# USB0_VBP2AHB_WRAP_CONTROLLER_VBP_USB3_CORE_GBL register map
Vendor: Texas Instruments
Peripheral module from a debugger description file (folder J722S).
Registers are 32-bit, read-write, reset 0x0 unless marked. A register's access mark holds for its fields unless they carry their own. Offsets are as the file gives them; lines under a group give offsets from that group; [hi:lo] are bit positions; {n}, {i} and the like mark numbered series; 'fields as' and 'values as' point back to an identical list; <NAME> marks a mode.

## USB0_VBP2AHB_WRAP_CONTROLLER_VBP_USB3_CORE_GBL (part 1 of 4)
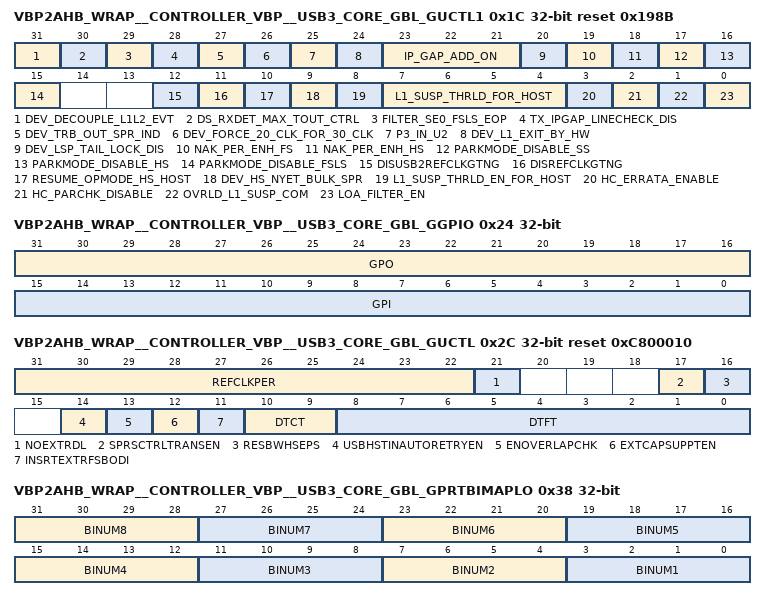
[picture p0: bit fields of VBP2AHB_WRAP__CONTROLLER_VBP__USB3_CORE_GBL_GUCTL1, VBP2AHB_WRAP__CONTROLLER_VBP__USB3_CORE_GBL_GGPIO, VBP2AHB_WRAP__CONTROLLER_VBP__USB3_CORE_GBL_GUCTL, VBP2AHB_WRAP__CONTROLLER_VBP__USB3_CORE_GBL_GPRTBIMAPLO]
0x1C VBP2AHB_WRAP__CONTROLLER_VBP__USB3_CORE_GBL_GUCTL1 access per field reset 0x198B — Global User Control Register 1
  [31] DEV_DECOUPLE_L1L2_EVT rw — DEV_DECOUPLE_L1L2_EVT - 0: Default behavior, no change in device events L1/L2U3 events are not decoupled [old behavior of v2.90a and before] - 1: Feature enabled, L1 and L2 events are separated when operating in 2.0 mode. Separate event enable bits for L1 suspend and wake events. This bit is applicable for device mode only. If this feature is enabled, L1 suspend and wake events have individual controls to enable/mask them. Enable this feature if you want to get L1 [LPM] events separtely and not combined with L2 events when operating in 2.0 speeds.
  [30] DS_RXDET_MAX_TOUT_CTRL rw — DS_RXDET_MAX_TOUT_CTRL This bit is used to control the tRxDetectTimeoutDFP timer for the SuperSpeed link. - 0: Default behavior. 12ms is used as tRxDetectTimeoutDFP. - 1: 120ms is used as the tRxDetectTimeoutDFP. This bit is used only in host mode. For more details, refer to ECN020 for USB 3.0 Specification.
  [29] FILTER_SE0_FSLS_EOP rw — FILTER_SE0_FSLS_EOP - 0: Default behavior, no change in Linestate check for SE0 detection in FS/LS - 1: Feature enabled, FS/LS SE0 is filtered for 2 clocks for detecting EOP This bit is applicable for FS/LS operation. If this feature is enabled, then SE0 on the linestate is validated for 2 consecutive utmi/ulpi clock edges for EOP detection. This feature is applicable only in FS in device mode and FS/LS mode of operation in host mode. Device mode: FS - If GUCTL1.FILTER_SE0_FSLS_EOP is set, then for device LPM handshake, the controller will ignore single SE0 glitch on the linestate during transmit. Only 2 or more SE0 is considered as a valid EOP on FS. Host mode: FS/LS - If GUCTL1.FILTER_SE0_FSLS_EOP is set, then the controller will ignore single SE0 glitch on the linestate during transmit. Only 2 or more SE0 is considered as a valid EOP on FS/LS port. Enable this feature if the LineState has SE0 glitches during transmission. This bit is quasi-static, that is, it must not be changed during device operation.
  [28] TX_IPGAP_LINECHECK_DIS rw — TX_IPGAP_LINECHECK_DIS - 0: Default behavior, no change in Linestate check - 1: Feature enabled, 2.0 MAC disables Linestate check during HS transmit This bit is applicable for HS operation of u2mac. If this feature is enabled, then the 2.0 mac operating in HS ignores the UTMI/ULPI Linestate during the transmit of a token [during token-to-token and token-to-data IPGAP]. When enabled, the controller implements a fixed 40-bit TxEndDelay after the packet is given on UTMI and ignores the Linestate during this time. This feature is applicable only in HS mode of operation. Device mode: If GUCTL1.TX_IPGAP_LINECHECK_DIS is set, then for device LPM handshake, the controller will ignore the linestate after TX and wait for fixed clocks [40 bit times equivalent] after transmitting ACK on utmi. Host mode: If GUCTL1.TX_IPGAP_LINECHECK_DIS is set, then the ipgap between [tkn to tkn/data] is added by 40 bit times of TXENDDELAY, and linestate is ignored during this 40 bit times delay. Enable this bit if the LineState will not reflect the expected line state [J] during transmission. This bit is quasi-static, that is, it must not be changed during device operation.
  [27] DEV_TRB_OUT_SPR_IND rw — DEV_TRB_OUT_SPR_IND - 0: Default behavior, no change in TRB status dword - 1: Feature enabled, OUT TRB status indicates Short Packet This bit is applicable for device mode only [and ignored in host mode]. If the device application [software/hardware] wants to know if a short packet was received for an OUT in the TRB status itself, then this feature can be enabled, so that a bit is set in the TRB writeback in the buf_size dword. Bit[26] - SPR of the {trbstatus, RSVD, SPR, PCM1, bufsize} dword will be set during an OUT transfer TRB write back if this is the last TRB used for that transfer descriptor. This bit is quasi-static, that is, it must not be changed during device operation.
  [26] DEV_FORCE_20_CLK_FOR_30_CLK rw — DEV_FORCE_20_CLK_FOR_30_CLK - 0: Default behavior, Uses 3.0 clock when operating in 2.0 mode - 1: Feature enabled This bit is applicable [and to be set] for device mode [DCFG.Speed != SS] only. In the 3.0 device controller, if the controller is programmed to operate in 2.0 only [that is, Device Speed is programmed to 2.0 speeds in DCFG[Speed]], then setting this bit makes the internal 2.0 [utmi/ulpi] clock to be routed as the 3.0 [pipe] clock. Enabling this feature allows the pipe3 clock to be not-running when forcibly operating in 2.0 device mode. Note: - When using this feature, all pipe3 inputs must be in inactive mode. In particular, the pipe3 clocks must not be running and the pipe3_phystatus_async must be tied to 0. This bit should not be set if the controller is programmed to operate in SuperSpeed mode [even when it falls back to 2.0]. - This bit is quasi-static, that is, it must not be changed during operation. - If the parameter DWC_USB3_REMOVE_PIPE_CLK_MUX_FOR_20_MODE is enabled, then muxing 2.0 clock/signals to pipe_clk/signals have to be done outside the controller for this feature to work.
  [25] P3_IN_U2 rw — P3_IN_U2 - 0: Default behavior, When SuperSpeed link is in U2, PowerState P2 is attempted on the PIPE Interface. - 1: When SuperSpeed link is in U2, PowerState P3 is attempted if GUSB3PIPECTL[17] is set. Setting this bit enables P3 Power State when the SuperSpeed link is in U2. Another Power Saving option. Check with your PHY vendor before enabling this option.When setting this bit to 1 to enable P3 in P2, GUSB3PIPECTL[27] should be set to 0 to make sure that the U2 exit is attempted in P0. This bit should be set only when GCTL.SOFITPSYNC=1 or GFLADJ.GFLADJ_REFCLK_LPM_SEL=1.
  [24] DEV_L1_EXIT_BY_HW rw — DEV_L1_EXIT_BY_HW - 0: Default behavior, disables device L1 hardware exit logic - 1: feature enabled This bit is applicable for device mode [2.0] only. This field enables device controller sending remote wakeup for L1 if the device becomes ready for sending/accepting data when in L1 state. If the host expects the device to send remote wakeup signaling to resume after going into L1 in flow controlled state, then this bit can be set to send the remote wake signal automatically when the device controller becomes ready. This hardware remote wake feature is applicable only to bulk and interrupt transfers, and not for Isoch/Control - When control transfers are in progress, the LPM will be rejected [NYET response]. Only after control transfers are completed [either with ACK/STALL], LPM will be accepted - For Isoch transfers, the host needs to do the wake-up and start the transfer. Device controller will not do remote-wakeup when Isoch endpoints get ready. The device SW needs to keep the GUSB2PHYCFG[EnblSlpM] reset in order to keep the PHY clock to be running for keeping track of SOF intervals. - When L1 hibernation is enabled, the controller will not do automatic exit for hibernation requests thru L1. This bit is quasi-static, that is, it must not be changed during device operation.
  [23:21] IP_GAP_ADD_ON rw — This register field is used to add on to the default inter packet gap setting in the USB 2.0 MAC. This should be programmed to a non zero value only in case where you need to increase the default inter packet delay calculations in the USB 2.0 MAC module DWC_usb3_u2mac.v
  [20] DEV_LSP_TAIL_LOCK_DIS rw — DEV_LSP_TAIL_LOCK_DIS - 0: Default behavior, enables device lsp lock logic for tail TRB update - 1: Fix disabled This is a bug fix for STAR 9000716195 that affects the CSP mode for OUT endpoints in device mode. The issue is that tail TRB index is not synchronized with the cache Scratchpad bytecount update. If the fast-forward request comes in-between the bytecount update on a newly fetched TRB and the tail-index write update in TPF, the RDP works on an incorrect tail index and misses the byte count decrement for the newly fetched TRB in the fast-forwarding process. This fix needs to be present all the times.
  [19] NAK_PER_ENH_FS rw — NAK_PER_ENH_FS - 1: Enables performance enhancement for FS async endpoints in the presence of NAKs - 0: Enhancement not applied If a periodic endpoint is present , and if a bulk endpoint which is also active is being NAKed by the device, then this could result in a decrease in performance of other Full Speed bulk endpoint which is ACked by the device. Setting this bit to 1, will enable the host controller to schedule more transactions to the async endpoints [bulk/ control] and hence will improve the performance of the bulk endpoint. This control bit should be enabled only if the existing performance with the default setting is not sufficient for your FullSpeed application. Setting this bit will only control, and is only required for Full Speed transfers.
  [18] NAK_PER_ENH_HS rw — NAK_PER_ENH_HS - 1: Enables performance enhancement for HS async endpoints in the presence of NAKs - 0: Enhancement not applied If a periodic endpoint is present, and if a bulk endpoint which is also active is being NAKed by the device, then this could result in decrease in performance of other High Speed bulk endpoint which is ACked by the device. Setting this bit to 1, will enable the host controller to schedule more transactions to the async endpoints [ bulk/ control] and hence will improve the performance of the bulk endpoint. This control bit should be enabled only if the existing performance with the default setting is not sufficient for your HighSpeed application. Setting this bit will only control, and is only required for High Speed transfers.
  [17] PARKMODE_DISABLE_SS rw — PARKMODE_DISABLE_SS This bit is used only in host mode, and is for debug purpose only. When this bit is set to '1' all SS bus instances in park mode are disabled.
  [16] PARKMODE_DISABLE_HS rw — PARKMODE_DISABLE_HS This bit is used only in host mode. When this bit is set to '1' all HS bus instances park mode are disabled. To improve performance in park mode, the xHCI scheduler queues in three requests of 4 packets each for High Speed asynchronous endpoints in a micro-frame. But if a device is slow and if it NAKs more than 3 times, then it is rescheduled only in the next micro-frame. This could decrease the performance of a slow device even further. In a few high speed devices [such as Sandisk Cruzer Blade 4GB VID:1921, PID:21863 and Flex Drive VID:3744, PID:8552] when an IN request is sent within 900ns of the ACK of the previous packet, these devices send a NAK. When connected to these devices, if required, the software can disable the park mode if you see performance drop in your system. When park mode is disabled, pipelining of multiple packet is disabled and instead one packet at a time is requested by the scheduler. This allows up to 12 NAKs in a micro-frame and improves performance of these slow devices.
  [15] PARKMODE_DISABLE_FSLS rw — PARKMODE_DISABLE_FSLS This bit is used only in host mode, and is for debug purpose only. When this bit is set to '1' all FS/LS bus instances in park mode disabled.
  [12] DISUSB2REFCLKGTNG ro — Disable ref_clk gating for 2.0 PHY [DisUSB2RefClkGtng] If ref_clk gating is disabled, then the ref_clk input cannot be turned off to the USB 2.0 PHY and controller. This is independent of the GCTL[DisClkGtng] setting. - 1'b0: ref_clk gating enabled for USB 2.0 PHY - 1'b1: ref_clk gating disabled for USB 2.0 PHY
  [11] DISREFCLKGTNG ro — Disable ref_clk gating [DisRefClkGtng] If the ref_clk gating is disabled then input ref_clk cannot be turned off to SSPHY and controller. This is independent of GCTL[DisClkGtng] setting. - 1'b0: ref_clk gating Enabled for SSPHY - 1'b1: ref_clk gating Disabled for SSPHY
  [10] RESUME_OPMODE_HS_HOST rw — RESUME_OPMODE_HS_HOST This bit is used only in host mode, and is for USB 2.0 opmode behavior in HS Resume. - When this bit is set to '1', the UTMI/ULPI opmode will be changed to normal along with HS terminations after EOR. This option is to support certain legacy UTMI/ULPI PHYs. - When this bit is set to '0', the UTMI/ULPI opmode will be changed to normal 2us after HS terminations change after EOR. This is the default behavior.
  [9] DEV_HS_NYET_BULK_SPR rw — DEV_HS_NYET_BULK_SPR - 0: Default behavior, no change in device response - 1: Feature enabled, HS bulk OUT short packet gets NYET response This bit is applicable for device mode only [and ignored in host mode] to be used in 2.0 operation. If this bit is set, the device controller sends NYET response instead of ACK response for a successfully received bulk OUT short packet. If NYET is sent after receiving short packet, then the host would PING before sending the next OUT. this improves the performance as well as clears up the buffer/cache on the host side. Internal to the device controller, short packet [SPR=1] processing takes some time, and during this time, the USB is flow controlled. With NYET response instead of ACK on short packet, the host does not send another OUT-DATA without pinging in HS mode. This bit is quasi-static, that is, it must not be changed during device operation.
  [8] L1_SUSP_THRLD_EN_FOR_HOST rw — L1_SUSP_THRLD_EN_FOR_HOST This bit is used only in host mode. The host controller asserts the utmi_l1_suspend_n and utmi_sleep_n output signals [see LPM Interface Signals table in the Databook] as follows: The controller asserts the utmi_l1_suspend_n signal to put the PHY into deep low-power mode in L1 when both of the following are true: - The HIRD/BESL value used is greater than or equal to the value in L1_SUSP_THRLD_FOR_HOST field. - The L1_SUSP_THRLD_EN_FOR_HOST bit is set to 1'b1. The controller asserts utmi_sleep_n on L1 when one of the following is true: - The HIRD/BESL value used is less than the value in L1_SUSP_THRLD_FOR_HOST field. - The L1_SUSP_THRLD_EN_FOR_HOST bit is set to 1'b0.
  [7:4] L1_SUSP_THRLD_FOR_HOST rw — L1_SUSP_THRLD_FOR_HOST This field is effective only when the L1_SUSP_THRLD_EN_FOR_HOST bit is set to 1. For more details, refer to the description of the L1_SUSP_THRLD_EN_FOR_HOST bit.
  [3] HC_ERRATA_ENABLE rw — Host ELD Enable [HELDEn] When this bit is set to 1, it enables the Exit Latency Delta [ELD] support defined in the xHCI 1.0 Errata. This bit is used only in the host mode. This bit has to be set to 1 in Host mode.
  [2] HC_PARCHK_DISABLE rw — Host Parameter Check Disable [HParChkDisable] When this bit is set to '0' [by default], the xHC checks that the input slot/EP context fields comply to the xHCI Specification. Upon detection of a parameter error during command execution, the xHC generates an event TRB with completion code indicating 'PARAMETER ERROR'. When the bit is set to '1', the xHC does not perform parameter checks and does not generate 'PARAMETER ERROR' completion code.
  [1] OVRLD_L1_SUSP_COM rw — OVRLD_L1_SUSP_COM If this bit is set, the utmi_l1_suspend_com_n is overloaded with the utmi_sleep_n signal. This bit is usually set if the PHY stops the port clock during L1 sleep condition. Note: The recommended connection for the SUSPENDM/SLEEPM signals to the PHY with respect to this bit is as follows. For non-zero ports: Connect: - utmi_sleep_n[n] to SLEEPM[n] - [utmi_suspend_n[n] & utmi_l1_suspend_n[n]] to SUSPENDM[n] - USB2 PHYCLK[n] to utmi_clk[n] GUCTL1.OVRLD_L1_SUSP_COM impacts only Port0. For Port0: For Synopsys PHY, GUSB2PHYCFGn.U2_FREECLK_EXISTS=1. With this connection, the PHY keeps PLL active so that FREECLK is always available irrespective of suspend/sleep. - Connect USB2 PHY COMMONONN to 0. - Connect utmi_sleep_n[0] to SLEEPM[0]. - Connect [utmi_suspend_n[0] & utmi_l1_suspend_n[0]] to SUSPENDM[0]. - Connect USB2 PHY FREECLK to utmi_clk[0]. - Leave utmi_suspend_com_n, utmi_l1_suspend_com_n unconnected. - GUCTL1.OVRLD_L1_SUSP_COM can be set to any value. For Third Party PHY, GUSB2PHYCFGn.U2_FREECLK_EXISTS=0. With this connection the PHY can shut off all the clocks when the required conditions are met [like, GUSB2PHYCFGn[8,6], GUCTL1[1], GFLADJ[23], GCTL[10], Suspend condition, HW LPM enable etc]. - Connect -utmi_suspend_com_n to SUSPENDM[0] [or equivalent]. - Connect -utmi_l1_suspend_com_n to SLEEPM[0] [or equivalent]. - Connect PHYCLK0 [first port clock] to utmi_clk[0]. - Leave utmi_suspend_n[0], utmi_l1_suspend_ n[0], utmi_sleep_n[0] unconnected. - Set GUCTL1.OVRLD_L1_SUSP_COM to 1'b1.
  [0] LOA_FILTER_EN rw — LOA_FILTER_EN If this bit is set, the USB 2.0 port babble is checked at least three consecutive times before the port is disabled. This prevents false triggering of the babble condition when using low quality cables. Note: This bit is valid only in host mode.
0x20 VBP2AHB_WRAP__CONTROLLER_VBP__USB3_CORE_GBL_GSNPSID ro reset 0x5533330B — Global Synopsys ID Register This is a read-only register that contains the release number of the controller.
  [31:0] SYNOPSYSID — Synopsys ID - SynopsysID[31:16] indicates Core Identification Number. 0x5533 is ASCII for U3 [DWC_usb3]. - SynopsysID[15:0] indicates the release number. Current Release is 3.30a. Software uses this register to configure release-specific features in the driver.
0x24 VBP2AHB_WRAP__CONTROLLER_VBP__USB3_CORE_GBL_GGPIO access per field — Global General Purpose Input/Output Register The application can use this register for general purpose input and output ports or for debugging.
  [31:16] GPO rw — General Purpose Output The value of this field is driven out on the gp_out[15:0] output port.
  [15:0] GPI ro — General Purpose Input The read value of this field reflects the gp_in[15:0] input signal value. Note: Register bit-bash test should not check for reset value of this field since its not predictable. depends on the gp_in port.
0x28 VBP2AHB_WRAP__CONTROLLER_VBP__USB3_CORE_GBL_GUID — Global User ID Register This is a read/write register containing the User ID. The power-on value for this register is specified as the User Identification Register. Power-on value during coreConsultant configuration (parameter DWC_USB3_USERID). This register can be used in the following ways: - To store the version or revision of your system. - To store hardware configurations that are outside the controller. - As a scratch register.
  [31:0] USERID — USERID Application-programmable ID field.
0x2C VBP2AHB_WRAP__CONTROLLER_VBP__USB3_CORE_GBL_GUCTL reset 0xC800010 — Global User Control Register: This register provides a few options for the software to control the controller behavior in the Host mode. Most of the options are used to improve host inter-operability with different devices.
  [31:22] REFCLKPER — REFCLKPER This field indicates in terms of nano seconds the period of ref_clk. The default value of this register is set to 'h8 [8ns/125 MHz]. This field needs to be updated during power-on initialization, if GCTL.SOFITPSYNC or GFLADJ.GFLADJ_REFCLK_LPM_SEL is set to '1'. The programmable maximum value is 62ns, and the minimum value is 8ns. You must use a reference clock with a period that is an integer multiple, so that ITP can meet the jitter margin of 32ns. The allowable ref_clk frequencies whose period is not integer multiples are 16/17/19.2/24/39.7MHz. This field must not be set to '0' at any time. If you never plan to use this feature, then set this field to 'h8, the default value.
  [21] NOEXTRDL — No Extra Delay Between SOF and the First Packet[NoExtrDl] Some HS devices misbehave when the host sends a packet immediately after a SOF. However, adding an extra delay between a SOF and the first packet can reduce the USB data rate and performance. This bit is used to control whether the host must wait for 2 microseconds before it sends the first packet after a SOF, or not. User can set this bit to one to improve the performance if those problematic devices are not a concern in the user's host environment. - 1'b0: Host waits for 2 microseconds after a SOF before it sends the first USB packet. - 1'b1: Host doesn't wait after a SOF before it sends the first USB packet.
  [17] SPRSCTRLTRANSEN — Sparse Control Transaction Enable Some devices are slow in responding to Control transfers. Scheduling multiple transactions in one microframe/frame can cause these devices to misbehave. If this bit is set to 1'b1, the host controller schedules transactions for a Control transfer in different microframes/frames.
  [16] RESBWHSEPS — Reserving 85% Bandwidth for HS Periodic EPs [ResBwHSEPS] By default, HC reserves 800f the bandwidth for periodic EPs. If this bit is set, the bandwidth is relaxed to 85% to accommodate two high speed, high bandwidth ISOC EPs. USB 2.0 required 800andwidth allocated for ISOC traffic. If two High-bandwidth ISOC devices [HD Webcams] are connected, and if each requires 1024-bytes X 3 packets per Micro-Frame, then the bandwidth required is around 82%. If this bit is set, then it is possible to connect two Webcams of 1024bytes X 3 paylod per Micro-Frame each. Otherwise, you may have to reduce the resolution of the Webcams. This bit is valid in Host and DRD configuration and is used in host mode operation only. Ignore this bit in device mode.
  [14] USBHSTINAUTORETRYEN — Host IN Auto Retry [USBHstInAutoRetryEn] When set, this field enables the Auto Retry feature. For IN transfers [non-isochronous] that encounter data packets with CRC errors or internal overrun scenarios, the auto retry feature causes the Host controller to reply to the device with a non-terminating retry ACK [that is, an ACK transaction packet with Retry = 1 and NumP != 0]. If the Auto Retry feature is disabled [default], the controller will respond with a terminating retry ACK [that is, an ACK transaction packet with Retry = 1 and NumP = 0]. - 1'b0: Auto Retry Disabled - 1'b1: Auto Retry Enabled Note: When enabling Auto Retry feature, if the system latency is large enough to cause the internal PSQ full [PSQ can be full as the result of messages not being processed because of pending fetches before flushing the TxQ due to NRDY/ERDY conditions], then the host controller can generate a transaction error.
  [13] ENOVERLAPCHK — Enable Check for LFPS Overlap During Remote Ux Exit: If this bit is set to, - 1'b1: The SuperSpeed link when exiting U1/U2/U3 waits for either the remote link LFPS or TS1/TS2 training symbols before it confirms that the LFPS handshake is complete. This is done to handle the case where the LFPS glitch causes the link to start exiting from the low power state. Looking for the LFPS overlap makes sure that the link partner also sees the LFPS. - 1'b0: When the link exists U1/U2/U3 because of a remote exit, it does not look for an LFPS overlap.
  [12] EXTCAPSUPPTEN — External Extended Capability Support Enable [ExtCapSuptEN] When set, this field enables extended capabilities to be implemented outside the controller. When the ExtCapSupEN is set and the Debug Capability is enabled, the Next Capability pointer in Debug Capability returns 16. A read to the first DWORD of the last internal extended capability [the xHCI Supported Protocol Capability for USB 3.0 when the Debug Capability is not enabled] returns a value of 4 in the Next Capability Pointer field. This indicates to software that there is another capability four DWORDs after this capability [for example, at address N+16 where N is the address of this DWORD]. If enabled, an external address decoder that snoops the xHC target interface must be implemented. If it sees an access to N+16 or greater, the target access is re-routed to a piece of hardware which returns the external capability pointer register of the new capability and also handles reads/writes to this new capability and the side effects. If disabled, a read to the first DWORD of the last internal extended capability returns 0 in the 'Next Capability Pointer field. This indicates there are no more capabilities.
  [11] INSRTEXTRFSBODI — Insert Extra Delay Between FS Bulk OUT Transactions [InsrtExtrFSBODl]. Some FS devices are slow to receive Bulk OUT data and can get stuck when there are consecutive Bulk OUT transactions with short inter-transaction delays. This bit is used to control whether the host inserts extra delay between consecutive Bulk OUT transactions to a FS Endpoint. - 1'b0: Host doesn't insert extra delay between consecutive Bulk OUT transactions to a FS Endpoint. - 1'b1: Host inserts about 12us extra delay between consecutive Bulk OUT transactions to a FS Endpoint to work around the device issue. Note: Setting this bit to one will reduce the Bulk OUT transfer performance for most of the FS devices.
  [10:9] DTCT — Device Timeout Coarse Tuning [DTCT] This field is a Host mode parameter which determines how long the host waits for a response from device before considering a timeout. The controller first checks the DTCT value. If it is 0, then the timeout value is defined by the DTFT. If it is non-zero, then it uses the following timeout values: - 2'b00: 0 usec -> use DTFT value instead - 2'b01: 500 usec - 2'b10: 1.5 msec - 2'b11: 6.5 msec Note: When the system latency is larger than the programmed DTCT/DTFT value, if the host controller is not able to accept certain transactions on the bus [because of system bus delays], the controller may not release header credits which in turn can cause the host to report a transaction error. Therefore, program this value to be larger than your system delay.
  [8:0] DTFT — Device Timeout Fine Tuning [DTFT] This field is a Host mode parameter which determines how long the host waits for a response from device before considering a timeout. For the DTFT field to take effect, DTCT must be set to 2'b00. The DTFT value is the number of 125 MHz clocks * 256 to count before considering a device timeout. The minimum value of DTFT is 2. For example, if the mac3_clk is 125 MHz clk [8 ns period], this is calculated as follows: [DTFT value] * 256 * [8 ns] Quick Reference: - if DTFT = 0x2, 2*256*8 = 4usec timeout - if DTFT = 0x5, 5*256*8 = 10usec timeout - if DTFT = 0xA, 10*256*8 = 20usec timeout - if DTFT = 0x10, 16*256*8 = 32usec timeout - if DTFT = 0x19, 25*256*8 = 51usec timeout - if DTFT = 0x31, 49*256*8 = 100usec timeout - if DTFT = 0x62, 98*256*8 = 200usec timeout Note: When the system latency is larger than the programmed DTCT/DTFT value, if the host controller is not able to accept certain transactions on the bus [because of system bus delays], the controller may not release header credits which in turn can cause the host to report a transaction error. Therefore, program this value to be larger than your system delay.
0x30 VBP2AHB_WRAP__CONTROLLER_VBP__USB3_CORE_GBL_GBUSERRADDRLO ro — Gobal SoC Bus Error Address Register - Low This is an alternate register for the GBUSERRADDR register.
  [31:0] BUSERRADDR — Bus Address - Low [BusAddrLo] This register contains the lower 32 bits of the first bus address that encountered a SoC bus error. It is valid when the GSTS.BusErrAddrVld field is 1. It can only be cleared by resetting the controller. Note: Only supported in AHB and AXI configurations.
0x34 VBP2AHB_WRAP__CONTROLLER_VBP__USB3_CORE_GBL_GBUSERRADDRHI ro — Gobal SoC Bus Error Address Register - High This is an alternate register for the GBUSERRADDR register.
  [31:0] BUSERRADDR — Bus Address - High [BusAddrHi] This register contains the higher 32 bits of the first bus address that encountered a SoC bus error. It is valid when the GSTS.BusErrAddrVld field is 1. It can only be cleared by resetting the controller. Note: Only supported in AHB and AXI configurations.
0x38 VBP2AHB_WRAP__CONTROLLER_VBP__USB3_CORE_GBL_GPRTBIMAPLO access per field — Global SS Port to Bus Instance Mapping Register - Low This is an alternate register for the GPRTBIMAP register. Register fields are read-write with respect to number of port instantiated. writeAsRead constraint is added to limit side effects for unused fields. For a configuration with number of USB 3.0 ports same as number of SS Bus Instances, do not remap during debug session. If you remap for some reason, then the debug host must be connected to a port which has a dedicated SS Bus Instance. For example, if DWC_USB3_NUM_U3_ROOT_PORTS =3 and DWC_USB3_NUM_SS_USB_INSTANCES=3, and software maps the first SS port to the first SS BI and the second/third port to the second BI, then the debug host can be connected to the first port only. Note: For reset values, refer to the corresponding values in the GPRTBIMAP register.
  [4n-1:4n-4] BINUM{n} ro (n=2..8) — BINUM{n}: SS USB Instance Number for Port {n}. Application-programmable ID field.
  [3:0] BINUM1 rw — BINUM1: SS USB Instance Number for Port 1. Application-programmable ID field.
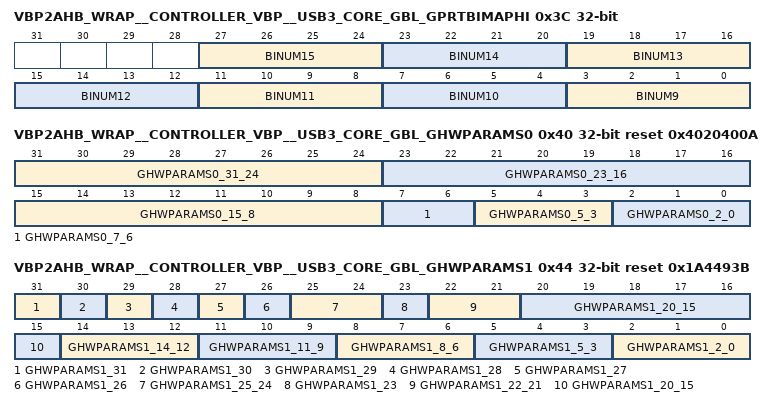
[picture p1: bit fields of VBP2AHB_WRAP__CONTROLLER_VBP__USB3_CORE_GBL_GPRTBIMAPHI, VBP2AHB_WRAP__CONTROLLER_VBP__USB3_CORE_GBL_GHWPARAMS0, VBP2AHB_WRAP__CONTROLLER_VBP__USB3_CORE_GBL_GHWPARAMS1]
0x3C VBP2AHB_WRAP__CONTROLLER_VBP__USB3_CORE_GBL_GPRTBIMAPHI ro — Global SS Port to Bus Instance Mapping Register - High This is an alternate register for the GPRTBIMAP register. For a configuration with number of USB 3.0 ports same as number of SS Bus Instances, do not remap during debug session. If you remap for some reason, then the debug host must be connected to a port which has a dedicated SS Bus Instance. For example, if DWC_USB3_NUM_U3_ROOT_PORTS =3 and DWC_USB3_NUM_SS_USB_INSTANCES=3, and software maps the first SS port to the first SS BI and the second/third port to the second BI, then the debug host can be connected to the first port only. Note: For reset values, refer to the corresponding values in the GPRTBIMAP register.
  [4n-33:4n-36] BINUM{n} (n=9..15) — BINUM{n}: SS USB Instance Number for Port {n}. Application-programmable ID field.
0x40 VBP2AHB_WRAP__CONTROLLER_VBP__USB3_CORE_GBL_GHWPARAMS0 ro reset 0x4020400A — Global Hardware Parameters Register 0 This register contains the hardware configuration options that you can select in the coreConsultant GUI. For a description of each parameter, refer to the Parameter Descriptions chapter in the Databook. This information is also available in coreConsultant by right-clicking the parameter label and selecting What's This or by clicking the Help tab. Note: Some of the global hardware parameters are not currently modifiable in coreConsultant. These settings are in the &#60;workspace>/src/DWC_usb3_params.v file. you must not change them.
  [31:24] GHWPARAMS0_31_24 — DWC_USB3_AWIDTH
  [23:16] GHWPARAMS0_23_16 — DWC_USB3_SDWIDTH
  [15:8] GHWPARAMS0_15_8 — DWC_USB3_MDWIDTH
  [7:6] GHWPARAMS0_7_6 — DWC_USB3_SBUS_TYPE
  [5:3] GHWPARAMS0_5_3 — DWC_USB3_MBUS_TYPE
  [2:0] GHWPARAMS0_2_0 — DWC_USB3_MODE
0x44 VBP2AHB_WRAP__CONTROLLER_VBP__USB3_CORE_GBL_GHWPARAMS1 ro reset 0x1A4493B — Global Hardware Parameters Register 1 This register contains the hardware configuration options that you can select in the coreConsultant GUI. For a description of each parameter, refer to the Parameter Descriptions chapter in the Databook. This information is also available in coreConsultant by right-clicking the parameter label and selecting What's This or by clicking the Help tab. Note: Some of the global hardware parameters are not currently modifiable in coreConsultant. These settings are in the &#60;workspace>/src/DWC_usb3_params.v file. you must not change them.
  [31] GHWPARAMS1_31 — DWC_USB3_EN_DBC
  [30] GHWPARAMS1_30 — DWC_USB3_RM_OPT_FEATURES
  [29] GHWPARAMS1_29 — Reserved1
  [28] GHWPARAMS1_28 — DWC_USB3_RAM_BUS_CLKS_SYNC
  [27] GHWPARAMS1_27 — DWC_USB3_MAC_RAM_CLKS_SYNC
  [26] GHWPARAMS1_26 — DWC_USB3_MAC_PHY_CLKS_SYNC
  [25:24] GHWPARAMS1_25_24 — DWC_USB3_EN_PWROPT
  [23] GHWPARAMS1_23 — DWC_USB3_SPRAM_TYP
  [22:21] GHWPARAMS1_22_21 — DWC_USB3_NUM_RAMS
  [20:15] GHWPARAMS1_20_15 — DWC_USB3_DEVICE_NUM_INT For details on DWC_USB3_DEVICE_NUM_INT, refer to &#60;workspace>/src/DWC_usb3_params.v file.
  [14:12] GHWPARAMS1_14_12 — DWC_USB3_ASPACEWIDTH
  [11:9] GHWPARAMS1_11_9 — DWC_USB3_REQINFOWIDTH
  [8:6] GHWPARAMS1_8_6 — DWC_USB3_DATAINFOWIDTH
  [5:3] GHWPARAMS1_5_3 — DWC_USB3_BURSTWIDTH-1
  [2:0] GHWPARAMS1_2_0 — DWC_USB3_IDWIDTH-1
0x48 VBP2AHB_WRAP__CONTROLLER_VBP__USB3_CORE_GBL_GHWPARAMS2 ro — Global Hardware Parameters Register 2 This register contains the hardware configuration options that you can select in the coreConsultant GUI. For a description of each parameter, refer to the Parameter Descriptions chapter in the Databook. This information is also available in coreConsultant by right-clicking the parameter label and selecting What's This or by clicking the Help tab. Note: Some of the global hardware parameters are not currently modifiable in coreConsultant. These settings are in the &#60;workspace>/src/DWC_usb3_params.v file. you must not change them.
  [31:0] GHWPARAMS2_31_0 — DWC_USB3_USERID
